# BL808 register map
File version: 0.1
Registers are access not given, no defined reset value unless marked. A register's access mark holds for its fields unless they carry their own. Offsets are from the block's base; [hi:lo] are bit positions; {n}, {i} and the like mark numbered series.

## MM_MISC
Base 0x30000000
0x00 CPU0_Boot rw
  [31:0] reg_cpu0_rvba
0x04 CPU1_Boot rw
  [31:0] reg_cpu1_rvba
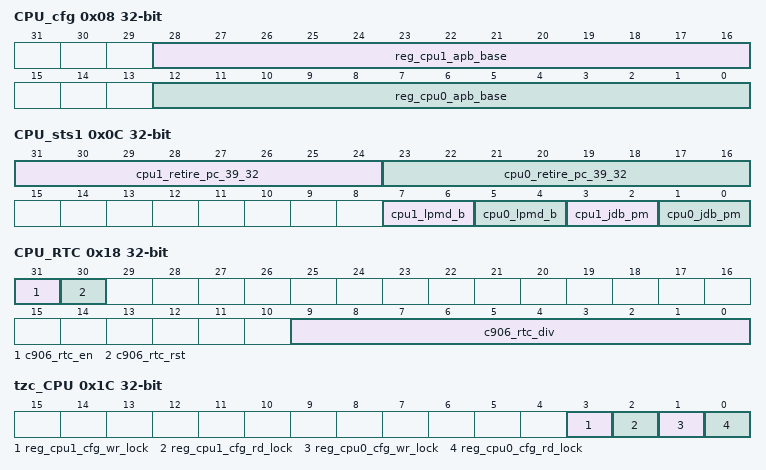
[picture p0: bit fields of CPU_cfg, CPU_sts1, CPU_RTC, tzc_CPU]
0x08 CPU_cfg
  [28:16] reg_cpu1_apb_base rw, [12:0] reg_cpu0_apb_base rw
0x0C CPU_sts1
  [31:24] cpu1_retire_pc_39_32 ro, [23:16] cpu0_retire_pc_39_32 ro, [7:6] cpu1_lpmd_b ro, [5:4] cpu0_lpmd_b ro, [3:2] cpu1_jdb_pm ro, [1:0] cpu0_jdb_pm ro
0x10 CPU_sts2 ro
  [31:0] cpu0_retire_pc_31_0
0x14 CPU_sts3 ro
  [31:0] cpu1_retire_pc_31_0
0x18 CPU_RTC
  [31] c906_rtc_en rw, [30] c906_rtc_rst rw, [9:0] c906_rtc_div rw
0x1C tzc_CPU
  [3] reg_cpu1_cfg_wr_lock rw, [2] reg_cpu1_cfg_rd_lock rw, [1] reg_cpu0_cfg_wr_lock rw, [0] reg_cpu0_cfg_rd_lock rw
0x20 peri_apb_ctrl
  [15:0] rg_pclk_force_on rw
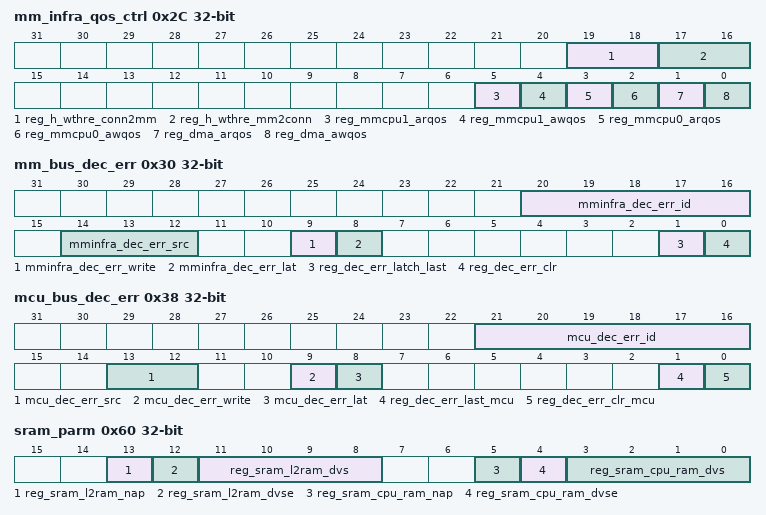
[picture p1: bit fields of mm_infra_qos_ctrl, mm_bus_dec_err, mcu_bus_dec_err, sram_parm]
0x2C mm_infra_qos_ctrl
  [19:18] reg_h_wthre_conn2mm rw, [17:16] reg_h_wthre_mm2conn rw, [5] reg_mmcpu1_arqos rw, [4] reg_mmcpu1_awqos rw, [3] reg_mmcpu0_arqos rw, [2] reg_mmcpu0_awqos rw, [1] reg_dma_arqos rw, [0] reg_dma_awqos rw
0x30 mm_bus_dec_err
  [20:16] mminfra_dec_err_id ro, [14:12] mminfra_dec_err_src ro, [9] mminfra_dec_err_write ro, [8] mminfra_dec_err_lat ro, [1] reg_dec_err_latch_last rw, [0] reg_dec_err_clr rw
0x34 mm_bus_dec_err_addr ro
  [31:0] mminfra_dec_err_addr
0x38 mcu_bus_dec_err
  [21:16] mcu_dec_err_id ro, [13:12] mcu_dec_err_src ro, [9] mcu_dec_err_write ro, [8] mcu_dec_err_lat ro, [1] reg_dec_err_last_mcu rw, [0] reg_dec_err_clr_mcu rw
0x3C mcu_bus_dec_err_addr ro
  [31:0] mcu_dec_err_addr
0x40 dma_clk_ctrl
  [7:0] dma_clk_en rw
0x50 sram_ctrl
  [0] reg_blai_sram_sel rw
0x60 sram_parm
  [13] reg_sram_l2ram_nap rw, [12] reg_sram_l2ram_dvse rw, [11:8] reg_sram_l2ram_dvs rw, [5] reg_sram_cpu_ram_nap rw, [4] reg_sram_cpu_ram_dvse rw, [3:0] reg_sram_cpu_ram_dvs rw
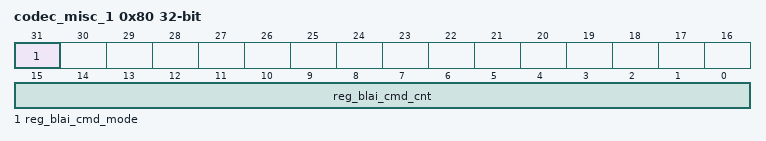
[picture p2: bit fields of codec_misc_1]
0x80 codec_misc_1
  [31] reg_blai_cmd_mode rw, [15:0] reg_blai_cmd_cnt rw
0xA0 MM_INT_STA0 ro
  [31:0] mm_int_sta0
0xA4 MM_INT_MASK0 rw
  [31:0] mm_int_mask0
0xA8 MM_INT_CLR0 write-once
  [31:0] mm_int_clr0
0xFC mmsys_misc_dummy rw
  [31:0] dummy_reg
0x100 DDR_debug
  [0] ddr_calib_done ro

## EMAC
Base 0x20070000
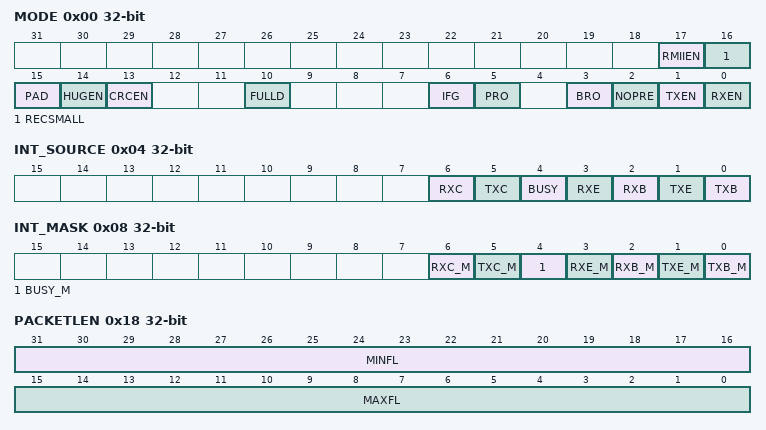
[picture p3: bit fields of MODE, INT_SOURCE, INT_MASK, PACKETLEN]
0x00 MODE
  [17] RMIIEN rw, [16] RECSMALL rw, [15] PAD rw, [14] HUGEN rw, [13] CRCEN rw, [10] FULLD rw, [6] IFG rw, [5] PRO rw, [3] BRO rw, [2] NOPRE rw, [1] TXEN rw, [0] RXEN rw
0x04 INT_SOURCE
  [6] RXC rw, [5] TXC rw, [4] BUSY rw, [3] RXE rw, [2] RXB rw, [1] TXE rw, [0] TXB rw
0x08 INT_MASK
  [6] RXC_M rw, [5] TXC_M rw, [4] BUSY_M rw, [3] RXE_M rw, [2] RXB_M rw, [1] TXE_M rw, [0] TXB_M rw
0x0C IPGT
  [6:0] IPGT rw
0x18 PACKETLEN rw
  [31:16] MINFL, [15:0] MAXFL
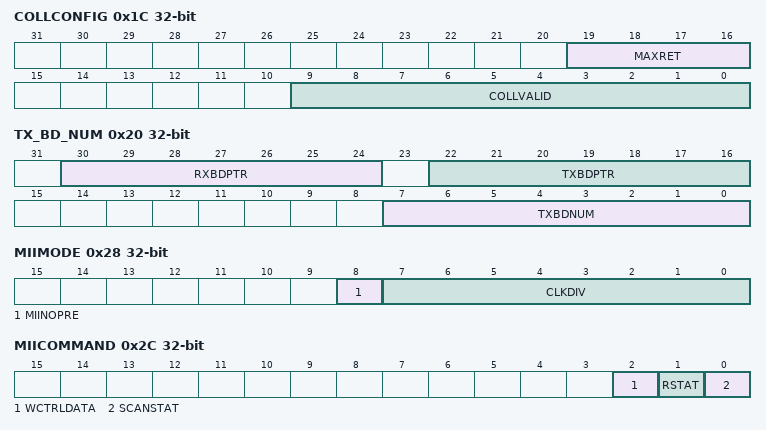
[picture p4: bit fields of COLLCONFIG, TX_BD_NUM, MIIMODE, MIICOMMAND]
0x1C COLLCONFIG
  [19:16] MAXRET rw, [9:0] COLLVALID rw
0x20 TX_BD_NUM
  [30:24] RXBDPTR ro, [22:16] TXBDPTR ro, [7:0] TXBDNUM rw
0x28 MIIMODE
  [8] MIINOPRE rw, [7:0] CLKDIV rw
0x2C MIICOMMAND
  [2] WCTRLDATA rw, [1] RSTAT rw, [0] SCANSTAT rw
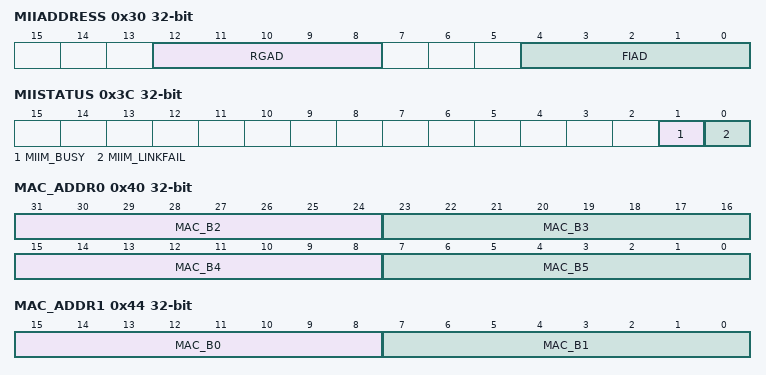
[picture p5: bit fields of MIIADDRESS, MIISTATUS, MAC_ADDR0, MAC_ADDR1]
0x30 MIIADDRESS
  [12:8] RGAD rw, [4:0] FIAD rw
0x34 MIITX_DATA
  [15:0] CTRLDATA rw
0x38 MIIRX_DATA
  [15:0] PRSD ro
0x3C MIISTATUS
  [1] MIIM_BUSY ro, [0] MIIM_LINKFAIL ro
0x40 MAC_ADDR0 rw
  [47-8n:40-8n] MAC_B{n} (n=2..5)
0x44 MAC_ADDR1
  [15:8] MAC_B0 rw, [7:0] MAC_B1 rw
0x48 HASH0_ADDR rw
  [31:0] HASH0
0x4C HASH1_ADDR rw
  [31:0] HASH1
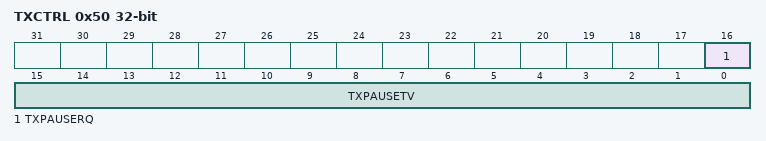
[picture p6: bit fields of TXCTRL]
0x50 TXCTRL
  [16] TXPAUSERQ rw, [15:0] TXPAUSETV rw

## LowPower
Base 0x2000F004
0x00 HBN_TIME_L rw
  [31:0] hbn_time_l — RTC timer compare bit 31:0
0x04 HBN_TIME_H
  [7:0] hbn_time_h rw — RTC timer compare bit 39:32

## LZ4D
Base 0x2000AD00
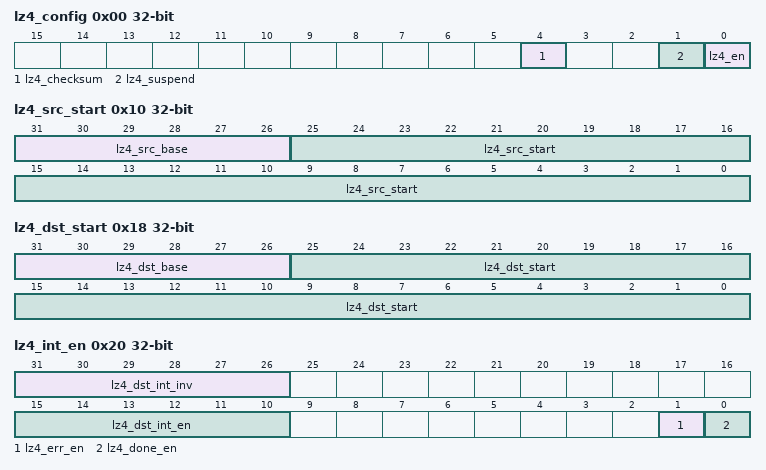
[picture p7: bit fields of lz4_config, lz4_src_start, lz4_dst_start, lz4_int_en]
0x00 lz4_config
  [4] lz4_checksum rw — LZ4 block has checksum or not (info from frame header checksum flag)
  [1] lz4_suspend rw — LZ4 blocks decode suspend (FSM idle)
  [0] lz4_en rw — LZ4 blocks decode enable (each block has size/sequences/checksum)
0x04 lz4_src_fix
  [25:12] lz4_src_fix rw — LZ4 source address fix bits
0x08 lz4_dst_fix
  [25:12] lz4_dst_fix rw — LZ4 destination address fix bits
0x10 lz4_src_start rw
  [31:26] lz4_src_base — LZ4 source address base (fix)
  [25:0] lz4_src_start — LZ4 source address start
0x14 lz4_src_end
  [25:0] lz4_src_end ro — LZ4 source address end (Max. 64MB)
0x18 lz4_dst_start rw
  [31:26] lz4_dst_base — LZ4 destination address base (fix)
  [25:0] lz4_dst_start — LZ4 destination address start
0x1C lz4_dst_end
  [25:0] lz4_dst_end ro — LZ4 destination address end (Max. 64MB)
0x20 lz4_int_en
  [31:26] lz4_dst_int_inv rw — 0: high int 1: low int
  [15:10] lz4_dst_int_en rw
  [1] lz4_err_en rw
  [0] lz4_done_en rw
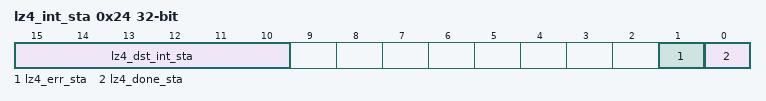
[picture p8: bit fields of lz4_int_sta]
0x24 lz4_int_sta
  [15:10] lz4_dst_int_sta ro — LZ4 destination address bit change
  [1] lz4_err_sta ro
  [0] lz4_done_sta ro — LZ4 done status
0x28 lz4_monitor
  [3:0] lz4_cs ro
